VERSION ""

NS_ :

BS_:

BU_: AMK_Inverter MCU

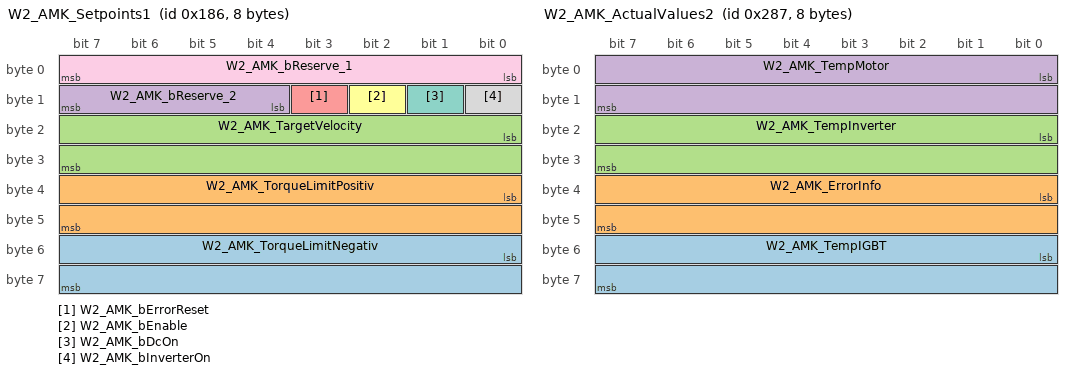
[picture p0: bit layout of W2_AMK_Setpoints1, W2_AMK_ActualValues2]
BO_ 390 W2_AMK_Setpoints1: 8 MCU
 SG_ W2_AMK_TorqueLimitNegativ : 48|16@1- (0.1,0) [-3276.8|3276.7] "% Mn"  AMK_Inverter
 SG_ W2_AMK_TorqueLimitPositiv : 32|16@1- (0.1,0) [-3276.8|3276.7] "% Mn"  AMK_Inverter
 SG_ W2_AMK_TargetVelocity : 16|16@1- (1,0) [-32768|32767] "rpm"  AMK_Inverter
 SG_ W2_AMK_bReserve_2 : 12|4@1+ (1,0) [0|0] ""  AMK_Inverter
 SG_ W2_AMK_bErrorReset : 11|1@1+ (1,0) [0|1] ""  AMK_Inverter
 SG_ W2_AMK_bEnable : 10|1@1+ (1,0) [0|1] ""  AMK_Inverter
 SG_ W2_AMK_bDcOn : 9|1@1+ (1,0) [0|1] ""  AMK_Inverter
 SG_ W2_AMK_bInverterOn : 8|1@1+ (1,0) [0|1] ""  AMK_Inverter
 SG_ W2_AMK_bReserve_1 : 0|8@1+ (1,0) [0|0] ""  AMK_Inverter

BO_ 647 W2_AMK_ActualValues2: 8 AMK_Inverter
 SG_ W2_AMK_TempIGBT : 48|16@1- (0.1,0) [-3276.8|3276.7] "°C"  MCU
 SG_ W2_AMK_ErrorInfo : 32|16@1+ (1,0) [0|65535] ""  MCU
 SG_ W2_AMK_TempInverter : 16|16@1- (0.1,0) [-3276.8|3276.7] "°C"  MCU
 SG_ W2_AMK_TempMotor : 0|16@1- (0.1,0) [-3276.8|3276.7] "°C"  MCU

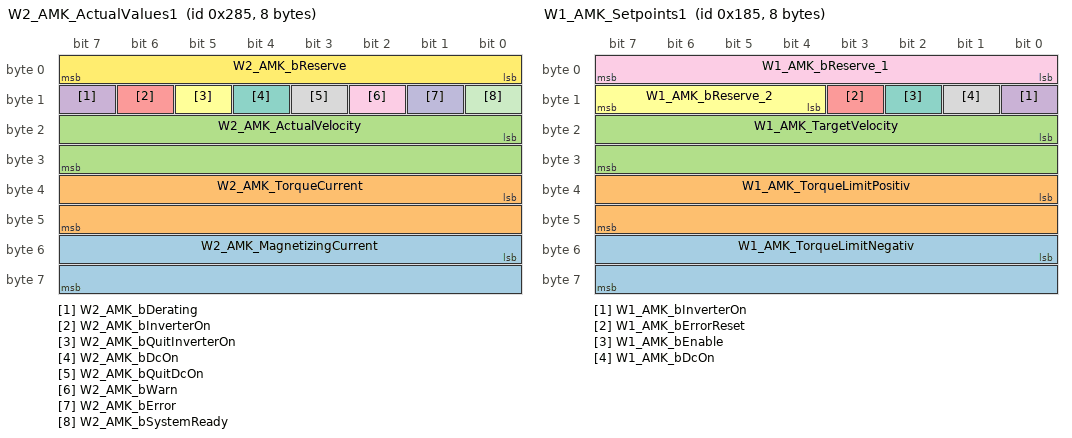
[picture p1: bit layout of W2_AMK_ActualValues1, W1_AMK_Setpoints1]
BO_ 645 W2_AMK_ActualValues1: 8 AMK_Inverter
 SG_ W2_AMK_MagnetizingCurrent : 48|16@1- (1,0) [-32768|32767] ""  MCU
 SG_ W2_AMK_TorqueCurrent : 32|16@1- (1,0) [-32768|32767] ""  MCU
 SG_ W2_AMK_ActualVelocity : 16|16@1- (1,0) [-32768|32767] "rpm"  MCU
 SG_ W2_AMK_bDerating : 15|1@1+ (1,0) [0|1] ""  MCU
 SG_ W2_AMK_bInverterOn : 14|1@1+ (1,0) [0|1] ""  MCU
 SG_ W2_AMK_bQuitInverterOn : 13|1@1+ (1,0) [0|1] ""  MCU
 SG_ W2_AMK_bDcOn : 12|1@1+ (1,0) [0|1] ""  MCU
 SG_ W2_AMK_bQuitDcOn : 11|1@1+ (1,0) [0|1] ""  MCU
 SG_ W2_AMK_bWarn : 10|1@1+ (1,0) [0|1] ""  MCU
 SG_ W2_AMK_bError : 9|1@1+ (1,0) [0|1] ""  MCU
 SG_ W2_AMK_bSystemReady : 8|1@1+ (1,0) [0|1] ""  MCU
 SG_ W2_AMK_bReserve : 0|8@1+ (1,0) [0|0] ""  MCU

BO_ 389 W1_AMK_Setpoints1: 8 MCU
 SG_ W1_AMK_TorqueLimitNegativ : 48|16@1- (0.1,0) [-3276.8|3276.7] "% Mn"  AMK_Inverter
 SG_ W1_AMK_TorqueLimitPositiv : 32|16@1- (0.1,0) [-3276.8|3276.7] "% Mn"  AMK_Inverter
 SG_ W1_AMK_TargetVelocity : 16|16@1- (1,0) [-32768|32767] "rpm"  AMK_Inverter
 SG_ W1_AMK_bInverterOn : 8|1@1+ (1,0) [0|1] ""  AMK_Inverter
 SG_ W1_AMK_bErrorReset : 11|1@1+ (1,0) [0|1] ""  AMK_Inverter
 SG_ W1_AMK_bReserve_2 : 12|4@1+ (1,0) [0|0] ""  AMK_Inverter
 SG_ W1_AMK_bEnable : 10|1@1+ (1,0) [0|1] ""  AMK_Inverter
 SG_ W1_AMK_bDcOn : 9|1@1+ (1,0) [0|1] ""  AMK_Inverter
 SG_ W1_AMK_bReserve_1 : 0|8@1+ (1,0) [0|0] ""  AMK_Inverter

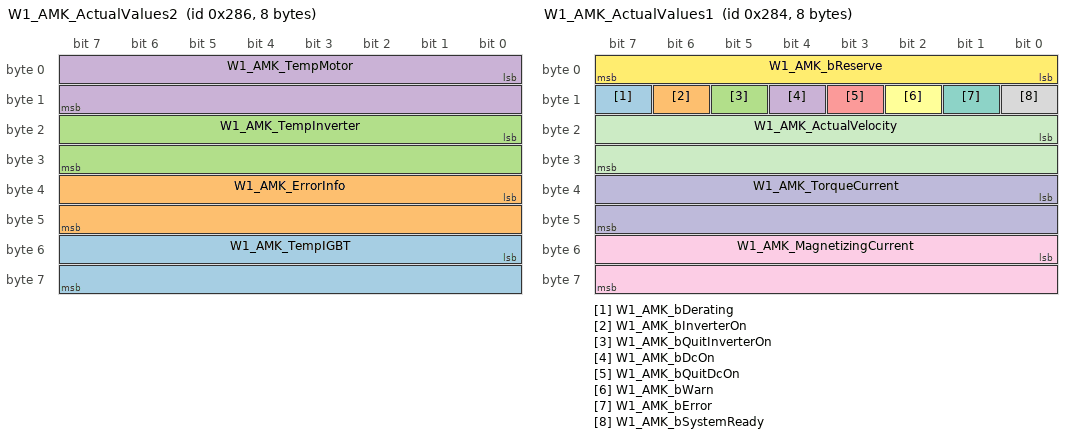
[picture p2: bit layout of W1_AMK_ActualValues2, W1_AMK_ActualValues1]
BO_ 646 W1_AMK_ActualValues2: 8 AMK_Inverter
 SG_ W1_AMK_TempIGBT : 48|16@1- (0.1,0) [-3276.8|3276.7] "°C"  MCU
 SG_ W1_AMK_ErrorInfo : 32|16@1+ (1,0) [0|65535] ""  MCU
 SG_ W1_AMK_TempInverter : 16|16@1- (0.1,0) [-3276.8|3276.7] "°C"  MCU
 SG_ W1_AMK_TempMotor : 0|16@1- (0.1,0) [-3276.8|3276.7] "°C"  MCU

BO_ 644 W1_AMK_ActualValues1: 8 AMK_Inverter
 SG_ W1_AMK_bDerating : 15|1@1+ (1,0) [0|1] ""  MCU
 SG_ W1_AMK_bInverterOn : 14|1@1+ (1,0) [0|1] ""  MCU
 SG_ W1_AMK_bQuitInverterOn : 13|1@1+ (1,0) [0|1] ""  MCU
 SG_ W1_AMK_bDcOn : 12|1@1+ (1,0) [0|1] ""  MCU
 SG_ W1_AMK_bQuitDcOn : 11|1@1+ (1,0) [0|1] ""  MCU
 SG_ W1_AMK_bWarn : 10|1@1+ (1,0) [0|1] ""  MCU
 SG_ W1_AMK_bError : 9|1@1+ (1,0) [0|1] ""  MCU
 SG_ W1_AMK_bSystemReady : 8|1@1+ (1,0) [0|1] ""  MCU
 SG_ W1_AMK_MagnetizingCurrent : 48|16@1- (1,0) [-32768|32767] ""  MCU
 SG_ W1_AMK_TorqueCurrent : 32|16@1- (1,0) [-32768|32767] ""  MCU
 SG_ W1_AMK_ActualVelocity : 16|16@1- (1,0) [-32768|32767] "rpm"  MCU
 SG_ W1_AMK_bReserve : 0|8@1+ (1,0) [0|0] ""  MCU

CM_ SG_ 390 W2_AMK_TorqueLimitNegativ "Momentengrenze negativ (abh. von Nennmoment)";
CM_ SG_ 390 W2_AMK_TorqueLimitPositiv "Momentengrenze positiv (abh. von Nennmoment)";
CM_ SG_ 390 W2_AMK_TargetVelocity "Drehzahlsollwert";
CM_ SG_ 390 W2_AMK_bReserve_2 "Reserviert";
CM_ SG_ 390 W2_AMK_bErrorReset "Fehler löschen";
CM_ SG_ 390 W2_AMK_bEnable "Antrieb Freigabe";
CM_ SG_ 390 W2_AMK_bDcOn "HV-Freischaltung";
CM_ SG_ 390 W2_AMK_bInverterOn "Reglerfreigabe";
CM_ SG_ 390 W2_AMK_bReserve_1 "Reserviert";
CM_ SG_ 647 W2_AMK_ErrorInfo "Diagnosenummer";
CM_ SG_ 645 W2_AMK_MagnetizingCurrent "Rohdaten zur Berechnung 'Istwert Magnetisierungsstrom'";
CM_ SG_ 645 W2_AMK_TorqueCurrent "Rohdaten zur Berechnung 'Istwert Drehmoment bildender Strom'";
CM_ SG_ 645 W2_AMK_ActualVelocity "Drehzahlistwert";
CM_ SG_ 645 W2_AMK_bDerating "Statuswort
";
CM_ SG_ 645 W2_AMK_bInverterOn "Statuswort
";
CM_ SG_ 645 W2_AMK_bQuitInverterOn "Statuswort
";
CM_ SG_ 645 W2_AMK_bDcOn "Statuswort
";
CM_ SG_ 645 W2_AMK_bQuitDcOn "Statuswort
";
CM_ SG_ 645 W2_AMK_bWarn "Statuswort
";
CM_ SG_ 645 W2_AMK_bError "Statuswort
";
CM_ SG_ 645 W2_AMK_bSystemReady "Statuswort
";
CM_ SG_ 645 W2_AMK_bReserve "Statuswort - Reserviert";
CM_ SG_ 389 W1_AMK_TorqueLimitNegativ "Momentengrenze negativ (abh. von Nennmoment)";
CM_ SG_ 389 W1_AMK_TorqueLimitPositiv "Momentengrenze positiv (abh. von Nennmoment)";
CM_ SG_ 389 W1_AMK_TargetVelocity "Drehzahlsollwert";
CM_ SG_ 389 W1_AMK_bInverterOn "Reglerfreigabe";
CM_ SG_ 389 W1_AMK_bErrorReset "Fehler löschen";
CM_ SG_ 389 W1_AMK_bReserve_2 "Reserviert";
CM_ SG_ 389 W1_AMK_bEnable "Antrieb Freigabe";
CM_ SG_ 389 W1_AMK_bDcOn "HV-Freischaltung";
CM_ SG_ 389 W1_AMK_bReserve_1 "Reserviert";
CM_ SG_ 646 W1_AMK_ErrorInfo "Diagnosenummer";
CM_ SG_ 644 W1_AMK_bDerating "Statuswort
";
CM_ SG_ 644 W1_AMK_bInverterOn "Statuswort
";
CM_ SG_ 644 W1_AMK_bQuitInverterOn "Statuswort
";
CM_ SG_ 644 W1_AMK_bDcOn "Statuswort
";
CM_ SG_ 644 W1_AMK_bQuitDcOn "Statuswort
";
CM_ SG_ 644 W1_AMK_bWarn "Statuswort
";
CM_ SG_ 644 W1_AMK_bError "Statuswort
";
CM_ SG_ 644 W1_AMK_bSystemReady "Statuswort
";
CM_ SG_ 644 W1_AMK_MagnetizingCurrent "Rohdaten zur Berechnung 'Istwert Magnetisierungsstrom'";
CM_ SG_ 644 W1_AMK_TorqueCurrent "Rohdaten zur Berechnung 'Istwert Drehmoment bildender Strom'";
CM_ SG_ 644 W1_AMK_ActualVelocity "Drehzahlistwert";
CM_ SG_ 644 W1_AMK_bReserve "Statuswort - Reserviert";
BA_DEF_ SG_  "GenSigSendType" ENUM  "Cyclic","OnWrite","OnWriteWithRepetition","OnChange","OnChangeWithRepetition","IfActive","IfActiveWithRepetition","NoSigSendType","NotUsed","NotUsed","NotUsed","NotUsed","NotUsed";
BA_DEF_ BO_  "GenMsgILSupport" ENUM  "No","Yes";
BA_DEF_ BO_  "GenMsgSendType2" ENUM  "Zyklisch","Ereignisgesteuert","dummy","Auf Anfrage";
BA_DEF_ BO_  "GenMsgFastOnStart" INT 10 500;
BA_DEF_ BO_  "GenMsgCycleTimeActive" INT 1 100;
BA_DEF_ BO_  "VFrameFormat" ENUM  "StandardCAN","ExtendedCAN","reserved","reserved","reserved","reserved","reserved","reserved","reserved","reserved","reserved","reserved","reserved","reserved","StandardCAN_FD","ExtendedCAN_FD";
BA_DEF_ BO_  "GenMsgSendType" ENUM  "Cyclic","NotUsed","NotUsed","NotUsed","NotUsed","NotUsed","NotUsed","IfActive","NoMsgSendType","NotUsed","vector_leerstring";
BA_DEF_ BO_  "GenMsgCycleTime" INT 0 50000;
BA_DEF_  "BusType" STRING ;
BA_DEF_DEF_  "GenSigSendType" "Cyclic";
BA_DEF_DEF_  "GenMsgILSupport" "Yes";
BA_DEF_DEF_  "GenMsgSendType2" "Zyklisch";
BA_DEF_DEF_  "GenMsgFastOnStart" 10;
BA_DEF_DEF_  "GenMsgCycleTimeActive" 10;
BA_DEF_DEF_  "VFrameFormat" "ExtendedCAN_FD";
BA_DEF_DEF_  "GenMsgSendType" "NoMsgSendType";
BA_DEF_DEF_  "GenMsgCycleTime" 0;
BA_DEF_DEF_  "BusType" "CAN";
BA_ "VFrameFormat" BO_ 390 0;
BA_ "GenMsgSendType" BO_ 390 0;
BA_ "GenMsgCycleTime" BO_ 390 10;
BA_ "VFrameFormat" BO_ 647 0;
BA_ "GenMsgSendType" BO_ 647 0;
BA_ "GenMsgCycleTime" BO_ 647 5;
BA_ "VFrameFormat" BO_ 645 0;
BA_ "GenMsgSendType" BO_ 645 0;
BA_ "GenMsgCycleTime" BO_ 645 5;
BA_ "VFrameFormat" BO_ 389 0;
BA_ "GenMsgSendType" BO_ 389 0;
BA_ "GenMsgCycleTime" BO_ 389 10;
BA_ "VFrameFormat" BO_ 646 0;
BA_ "GenMsgSendType" BO_ 646 0;
BA_ "GenMsgCycleTime" BO_ 646 5;
BA_ "VFrameFormat" BO_ 644 0;
BA_ "GenMsgSendType" BO_ 644 0;
BA_ "GenMsgCycleTime" BO_ 644 5;
